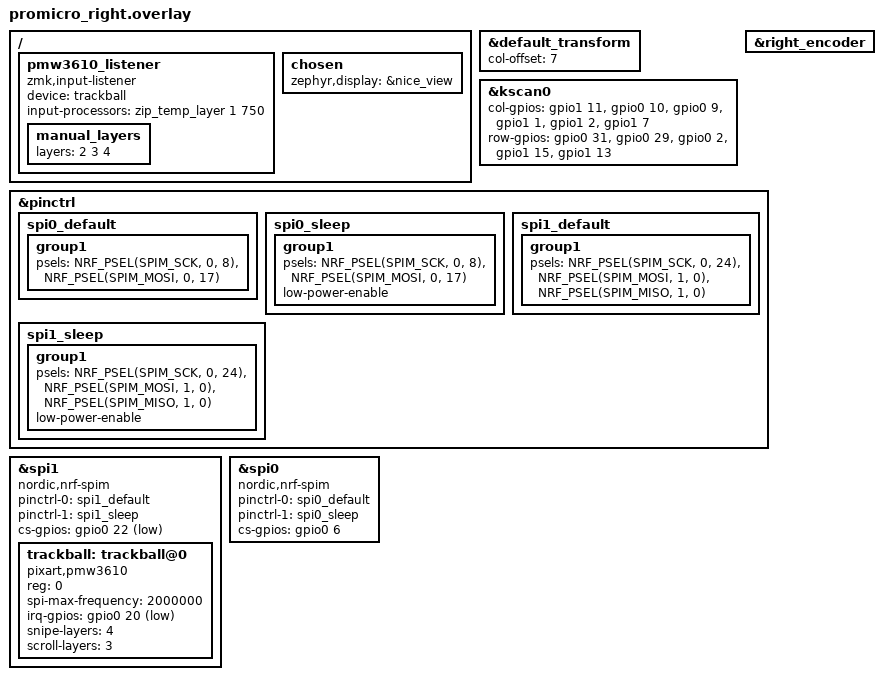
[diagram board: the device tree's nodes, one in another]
// promicro_left.overlay

#include "promicro.dtsi"
#include <input/processors.dtsi>

&default_transform {
    col-offset = <7>;
};

&kscan0 {
    col-gpios
	= <&gpio1 11  GPIO_ACTIVE_HIGH>  
	, <&gpio0 10  GPIO_ACTIVE_HIGH>  
        , <&gpio0 9  GPIO_ACTIVE_HIGH>  
	, <&gpio1 1  GPIO_ACTIVE_HIGH>  
	, <&gpio1 2  GPIO_ACTIVE_HIGH>  
	, <&gpio1 7  GPIO_ACTIVE_HIGH>
//	, <&gpio0 11 GPIO_ACTIVE_HIGH>
	;

     row-gpios
         = <&gpio0 31 (GPIO_ACTIVE_HIGH | GPIO_PULL_DOWN)>  
	 , <&gpio0 29  (GPIO_ACTIVE_HIGH | GPIO_PULL_DOWN)>  
         , <&gpio0 2  (GPIO_ACTIVE_HIGH | GPIO_PULL_DOWN)>  
	 , <&gpio1 15  (GPIO_ACTIVE_HIGH | GPIO_PULL_DOWN)> 
         , <&gpio1 13  (GPIO_ACTIVE_HIGH | GPIO_PULL_DOWN)>  
         ;
};

&right_encoder {
	status = "okay";
};

&pinctrl {
    spi0_default: spi0_default {
        group1 {
            psels = <NRF_PSEL(SPIM_SCK, 0, 8)>,
                <NRF_PSEL(SPIM_MOSI, 0, 17)>;
        };
    };
    spi0_sleep: spi0_sleep {
        group1 {
            psels = <NRF_PSEL(SPIM_SCK, 0, 8)>,
                <NRF_PSEL(SPIM_MOSI, 0, 17)>;
            low-power-enable;
        };
    };
    spi1_default: spi1_default {
        group1 {
            psels = <NRF_PSEL(SPIM_SCK, 0, 24)>,
                <NRF_PSEL(SPIM_MOSI, 1, 0)>,
                <NRF_PSEL(SPIM_MISO, 1, 0)>;
        };
    };
    spi1_sleep: spi1_sleep {
        group1 {
            psels = <NRF_PSEL(SPIM_SCK, 0, 24)>,
                <NRF_PSEL(SPIM_MOSI, 1, 0)>,
                <NRF_PSEL(SPIM_MISO, 1, 0)>;
            low-power-enable;
        };
    };
};

&spi1 {
  compatible = "nordic,nrf-spim";
  status = "okay";

  pinctrl-0 = <&spi1_default>;
  pinctrl-1 = <&spi1_sleep>;
  pinctrl-names = "default", "sleep";
  cs-gpios = <&gpio0 22 GPIO_ACTIVE_LOW>;
  trackball: trackball@0 {
      status = "okay";
      compatible = "pixart,pmw3610";
      reg = <0>;
      spi-max-frequency = <2000000>;
      irq-gpios = <&gpio0 20 (GPIO_ACTIVE_LOW | GPIO_PULL_UP)>;
      snipe-layers = <4>;
      scroll-layers = <3>;
      // Legacy automouse is disabled (binding default -1); use the official processor below.
  };
};

nice_view_spi: &spi0 {
    compatible = "nordic,nrf-spim";
    pinctrl-0 = <&spi0_default>;
    pinctrl-1 = <&spi0_sleep>;
    pinctrl-names = "default", "sleep";
    cs-gpios = <&gpio0 6 GPIO_ACTIVE_HIGH>;
};

/ {
  pmw3610_listener {
    compatible = "zmk,input-listener";
    device = <&trackball>;
    // Layer 1 is transparent and below every manual layer. Timeout is motion-based.
    input-processors = <&zip_temp_layer 1 750>;

    manual_layers {
      // Bluetooth, symbols/scroll, and function/snipe must keep their own behavior.
      layers = <2 3 4>;
      // No processors and no process-next: keep HID events, skip base processors.
    };
  };
};

/ {
    chosen {
        zephyr,display = &nice_view;
    };
};
